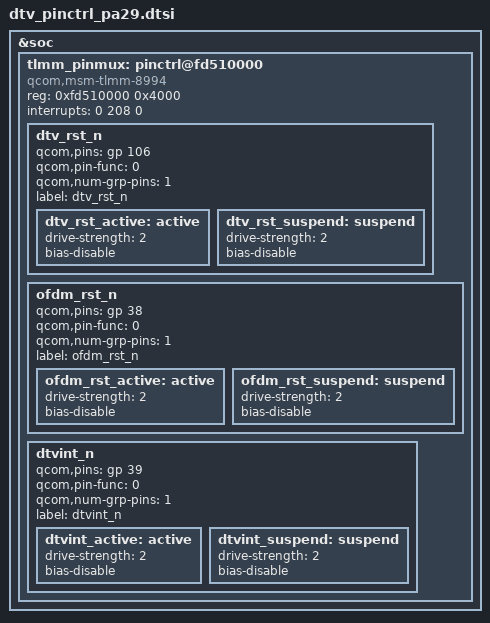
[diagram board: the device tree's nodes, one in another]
/* Copyright (c) 2013-2014, The Linux Foundation. All rights reserved.
 *
 * This program is free software; you can redistribute it and/or modify
 * it under the terms of the GNU General Public License version 2 and
 * only version 2 as published by the Free Software Foundation.
 *
 * This program is distributed in the hope that it will be useful,
 * but WITHOUT ANY WARRANTY; without even the implied warranty of
 * MERCHANTABILITY or FITNESS FOR A PARTICULAR PURPOSE.  See the
 * GNU General Public License for more details.
 */

&soc {
	tlmm_pinmux: pinctrl@fd510000 {
		compatible = "qcom,msm-tlmm-8994", "qcom,msm-tlmm-8974";
		reg = <0xfd510000 0x4000>;
		interrupts = <0 208 0>;

		/*****************************************/
		/*  pinctrl customize setting            */
		/*****************************************/
		dtv_rst_n {
			/* GPIO_106 */
			qcom,pins = <&gp 106>;
			qcom,pin-func = <0>;
			qcom,num-grp-pins = <1>;
			label = "dtv_rst_n";

			dtv_rst_active: active {
				drive-strength = <2>;
				bias-disable;
			};

			dtv_rst_suspend: suspend {
				drive-strength = <2>;
				bias-disable;
			};
		};

		ofdm_rst_n {
			/* GPIO_38 */
			qcom,pins = <&gp 38>;
			qcom,pin-func = <0>;
			qcom,num-grp-pins = <1>;
			label = "ofdm_rst_n";

			ofdm_rst_active: active {
				drive-strength = <2>;
				bias-disable;
			};

			ofdm_rst_suspend: suspend {
				drive-strength = <2>;
				bias-disable;
			};
		};

		dtvint_n {
			/* GPIO_39 */
			qcom,pins = <&gp 39>;
			qcom,pin-func = <0>;
			qcom,num-grp-pins = <1>;
			label = "dtvint_n";

			dtvint_active: active {
				drive-strength = <2>;
				bias-disable;			/* ExtPU? */
			};

			dtvint_suspend: suspend {
				drive-strength = <2>;
				bias-disable;			/* ExtPU? */
			};
		};

	};
};

